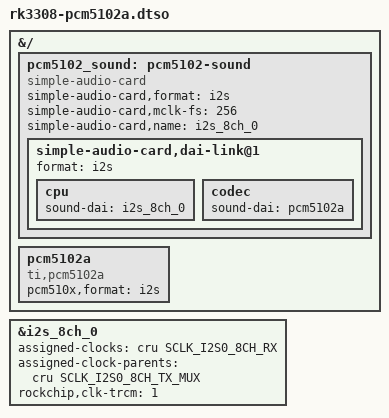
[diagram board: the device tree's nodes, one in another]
// Enable PCM510x

#include <dt-bindings/clock/rk3308-cru.h>

/dts-v1/;
/plugin/;

&{/} {
	pcm5102_sound: pcm5102-sound {
		compatible = "simple-audio-card";
		simple-audio-card,format = "i2s";
		simple-audio-card,mclk-fs = <256>;
		simple-audio-card,name = "i2s_8ch_0";

		simple-audio-card,dai-link@1 {
			format = "i2s";
			cpu {
				sound-dai = <&i2s_8ch_0>;
			};

			codec {
				sound-dai = <&pcm5102a>;
			};
		};
	};

	pcm5102a: pcm5102a {
		#sound-dai-cells = <0>;
		compatible = "ti,pcm5102a";
		pcm510x,format = "i2s";
	};
};

&i2s_8ch_0 {
	assigned-clocks = <&cru SCLK_I2S0_8CH_RX>;
	assigned-clock-parents = <&cru SCLK_I2S0_8CH_TX_MUX>;
	rockchip,clk-trcm = <1>;
	#sound-dai-cells = <0>;
	status = "okay";
};
